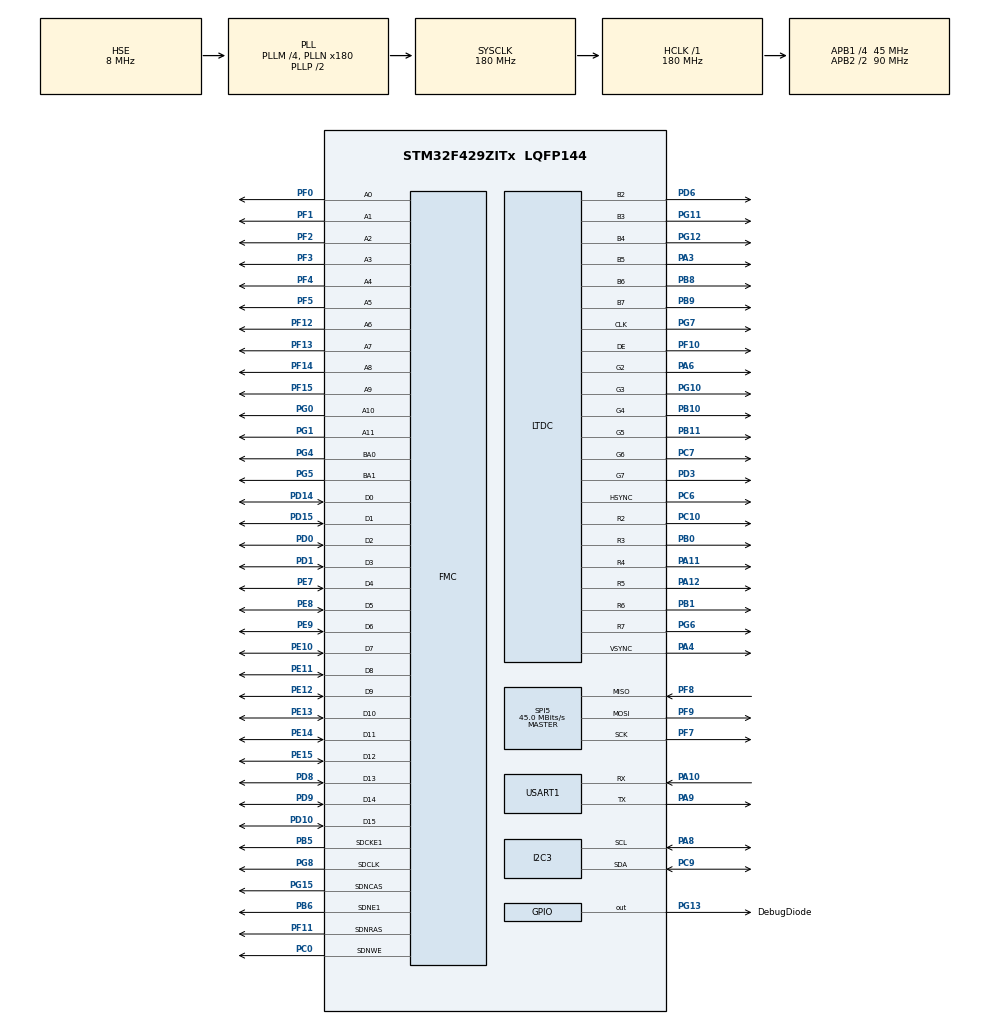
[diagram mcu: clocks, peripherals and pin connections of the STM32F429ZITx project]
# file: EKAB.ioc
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DMA2D.Mode=DMA2D_R2M
FMC.CASLatency1=FMC_SDRAM_CAS_LATENCY_3
FMC.ExitSelfRefreshDelay1=7
FMC.LoadToActiveDelay1=2
FMC.RCDDelay1=2
FMC.RPDelay1=2
FMC.RPDelay2=2
FMC.RowCycleDelay1=7
FMC.RowCycleDelay2=7
FMC.SDClockPeriod1=FMC_SDRAM_CLOCK_PERIOD_3
FMC.SDClockPeriod2=FMC_SDRAM_CLOCK_PERIOD_3
FMC.SelfRefreshTime1=4
FMC.WriteRecoveryTime1=3
FREERTOS.Tasks01=mainTask,24,128,mainTaskfunction,Default,NULL,Dynamic,NULL,NULL;painterTask,24,128,painterTaskFunction,Default,NULL,Dynamic,NULL,NULL
LTDC.ActiveH=320
LTDC.ActiveW=240
Mcu.Family=STM32F4
Mcu.Name=STM32F429ZITx
Mcu.Package=LQFP144
NVIC.PriorityGroup=NVIC_PRIORITYGROUP_4
NVIC.TIM6_DAC_IRQn=true\:0\:0\:false\:false\:true\:false\:false\:true
NVIC.TimeBase=TIM6_DAC_IRQn
NVIC.TimeBaseIP=TIM6
PA10.Mode=Asynchronous
PA10.Signal=USART1_RX
PA11.Mode=RGB666
PA11.Signal=LTDC_R4
PA12.Mode=RGB666
PA12.Signal=LTDC_R5
PA13.Mode=Serial_Wire
PA13.Signal=SYS_JTMS-SWDIO
PA14.Mode=Serial_Wire
PA14.Signal=SYS_JTCK-SWCLK
PA3.Mode=RGB666
PA3.Signal=LTDC_B5
PA4.Mode=RGB666
PA4.Signal=LTDC_VSYNC
PA6.Mode=RGB666
PA6.Signal=LTDC_G2
PA8.Mode=I2C
PA8.Signal=I2C3_SCL
PA9.Mode=Asynchronous
PA9.Signal=USART1_TX
PB0.Mode=RGB666
PB0.Signal=LTDC_R3
PB1.Mode=RGB666
PB1.Signal=LTDC_R6
PB10.Mode=RGB666
PB10.Signal=LTDC_G4
PB11.Mode=RGB666
PB11.Signal=LTDC_G5
PB5.Mode=SdramChipSelect2_1
PB5.Signal=FMC_SDCKE1
PB6.Mode=SdramChipSelect2_1
PB6.Signal=FMC_SDNE1
PB8.Mode=RGB666
PB8.Signal=LTDC_B6
PB9.Mode=RGB666
PB9.Signal=LTDC_B7
PC0.Signal=FMC_SDNWE
PC10.Mode=RGB666
PC10.Signal=LTDC_R2
PC6.Mode=RGB666
PC6.Signal=LTDC_HSYNC
PC7.Mode=RGB666
PC7.Signal=LTDC_G6
PC9.Mode=I2C
PC9.Signal=I2C3_SDA
PD0.Signal=FMC_D2_DA2
PD1.Signal=FMC_D3_DA3
PD10.Signal=FMC_D15_DA15
PD14.Signal=FMC_D0_DA0
PD15.Signal=FMC_D1_DA1
PD3.Mode=RGB666
PD3.Signal=LTDC_G7
PD6.Mode=RGB666
PD6.Signal=LTDC_B2
PD8.Signal=FMC_D13_DA13
PD9.Signal=FMC_D14_DA14
PE10.Signal=FMC_D7_DA7
PE11.Signal=FMC_D8_DA8
PE12.Signal=FMC_D9_DA9
PE13.Signal=FMC_D10_DA10
PE14.Signal=FMC_D11_DA11
PE15.Signal=FMC_D12_DA12
PE7.Signal=FMC_D4_DA4
PE8.Signal=FMC_D5_DA5
PE9.Signal=FMC_D6_DA6
PF0.Signal=FMC_A0
PF1.Signal=FMC_A1
PF10.Mode=RGB666
PF10.Signal=LTDC_DE
PF11.Signal=FMC_SDNRAS
PF12.Signal=FMC_A6
PF13.Signal=FMC_A7
PF14.Signal=FMC_A8
PF15.Signal=FMC_A9
PF2.Signal=FMC_A2
PF3.Signal=FMC_A3
PF4.Signal=FMC_A4
PF5.Signal=FMC_A5
PF7.Mode=Full_Duplex_Master
PF7.Signal=SPI5_SCK
PF8.Mode=Full_Duplex_Master
PF8.Signal=SPI5_MISO
PF9.Mode=Full_Duplex_Master
PF9.Signal=SPI5_MOSI
PG0.Signal=FMC_A10
PG1.Signal=FMC_A11
PG10.Mode=RGB666
PG10.Signal=LTDC_G3
PG11.Mode=RGB666
PG11.Signal=LTDC_B3
PG12.Mode=RGB666
PG12.Signal=LTDC_B4
PG13.GPIO_Label=DebugDiode
PG13.GPIO_ModeDefaultOutputPP=GPIO_MODE_OUTPUT_PP
PG13.Signal=GPIO_Output
PG15.Signal=FMC_SDNCAS
PG4.Signal=FMC_A14_BA0
PG5.Signal=FMC_A15_BA1
PG6.Mode=RGB666
PG6.Signal=LTDC_R7
PG7.Mode=RGB666
PG7.Signal=LTDC_CLK
PG8.Signal=FMC_SDCLK
PH0/OSC_IN.Mode=HSE-External-Oscillator
PH0/OSC_IN.Signal=RCC_OSC_IN
PH1/OSC_OUT.Mode=HSE-External-Oscillator
PH1/OSC_OUT.Signal=RCC_OSC_OUT
ProjectManager.HeapSize=0x200
ProjectManager.StackSize=0x400
ProjectManager.TargetToolchain=STM32CubeIDE
RCC.48MHZClocksFreq_Value=90000000
RCC.AHBFreq_Value=180000000
RCC.APB1CLKDivider=RCC_HCLK_DIV4
RCC.APB1Freq_Value=45000000
RCC.APB1TimFreq_Value=90000000
RCC.APB2CLKDivider=RCC_HCLK_DIV2
RCC.APB2Freq_Value=90000000
RCC.APB2TimFreq_Value=180000000
RCC.CortexFreq_Value=180000000
RCC.HCLKFreq_Value=180000000
RCC.HSE_VALUE=8000000
RCC.HSI_VALUE=16000000
RCC.LSE_VALUE=32768
RCC.PLLM=4
RCC.PLLN=180
RCC.PLLSAIDivR=RCC_PLLSAIDIVR_8
RCC.PLLSAIN=192
RCC.PLLSAIR=4
RCC.PLLSourceVirtual=RCC_PLLSOURCE_HSE
RCC.PWR_Regulator_Voltage_Scale=PWR_REGULATOR_VOLTAGE_SCALE1
RCC.SYSCLKFreq_VALUE=180000000
RCC.SYSCLKSource=RCC_SYSCLKSOURCE_PLLCLK
RCC.VCOOutputFreq_Value=360000000
SH.FMC_A0.0=FMC_A0,12b-sda1
SH.FMC_A1.0=FMC_A1,12b-sda1
SH.FMC_A10.0=FMC_A10,12b-sda1
SH.FMC_A11.0=FMC_A11,12b-sda1
SH.FMC_A14_BA0.0=FMC_BA0,FourSdramBanks1
SH.FMC_A15_BA1.0=FMC_BA1,FourSdramBanks1
SH.FMC_A2.0=FMC_A2,12b-sda1
SH.FMC_A3.0=FMC_A3,12b-sda1
SH.FMC_A4.0=FMC_A4,12b-sda1
SH.FMC_A5.0=FMC_A5,12b-sda1
SH.FMC_A6.0=FMC_A6,12b-sda1
SH.FMC_A7.0=FMC_A7,12b-sda1
SH.FMC_A8.0=FMC_A8,12b-sda1
SH.FMC_A9.0=FMC_A9,12b-sda1
SH.FMC_D0_DA0.0=FMC_D0,sd-16b-d1
SH.FMC_D10_DA10.0=FMC_D10,sd-16b-d1
SH.FMC_D11_DA11.0=FMC_D11,sd-16b-d1
SH.FMC_D12_DA12.0=FMC_D12,sd-16b-d1
SH.FMC_D13_DA13.0=FMC_D13,sd-16b-d1
SH.FMC_D14_DA14.0=FMC_D14,sd-16b-d1
SH.FMC_D15_DA15.0=FMC_D15,sd-16b-d1
SH.FMC_D1_DA1.0=FMC_D1,sd-16b-d1
SH.FMC_D2_DA2.0=FMC_D2,sd-16b-d1
SH.FMC_D3_DA3.0=FMC_D3,sd-16b-d1
SH.FMC_D4_DA4.0=FMC_D4,sd-16b-d1
SH.FMC_D5_DA5.0=FMC_D5,sd-16b-d1
SH.FMC_D6_DA6.0=FMC_D6,sd-16b-d1
SH.FMC_D7_DA7.0=FMC_D7,sd-16b-d1
SH.FMC_D8_DA8.0=FMC_D8,sd-16b-d1
SH.FMC_D9_DA9.0=FMC_D9,sd-16b-d1
SH.FMC_SDCLK.0=FMC_SDCLK,12b-sda1
SH.FMC_SDNCAS.0=FMC_SDNCAS,12b-sda1
SH.FMC_SDNRAS.0=FMC_SDNRAS,12b-sda1
SH.FMC_SDNWE.0=FMC_SDNWE,12b-sda1
SPI5.BaudRatePrescaler=SPI_BAUDRATEPRESCALER_2
SPI5.CalculateBaudRate=45.0 MBits/s
SPI5.Direction=SPI_DIRECTION_2LINES
SPI5.Mode=SPI_MODE_MASTER
SPI5.VirtualType=VM_MASTER
USART1.VirtualMode=VM_ASYNC
VP_DMA2D_VS_DMA2D.Mode=DMA2D_Activate
VP_FREERTOS_VS_CMSIS_V2.Mode=CMSIS_V2
VP_SYS_VS_tim6.Mode=TIM6
board=custom

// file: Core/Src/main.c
/* USER CODE BEGIN Header */
/**
 ******************************************************************************
 * @file           : main.c
 * @brief          : Main program body
 ******************************************************************************
 * @attention
 *
 * <h2><center>&copy; Copyright (c) 2020 STMicroelectronics.
 * All rights reserved.</center></h2>
 *
 * This software component is licensed by ST under BSD 3-Clause license,
 * the "License"; You may not use this file except in compliance with the
 * License. You may obtain a copy of the License at:
 *                        opensource.org/licenses/BSD-3-Clause
 *
 ******************************************************************************
 */
/* USER CODE END Header */

#include "main.h"
#include "cmsis_os.h"
#include "dma2d.h"
#include "i2c.h"
#include "ltdc.h"
#include "spi.h"
#include "usart.h"
#include "gpio.h"
#include "fmc.h"

/* USER CODE BEGIN Includes */
#include "chooseViewStructure.h"
#include "paintIntro.h"
#include "paintInterface.h"
#include "chooseCanvaInterface.h"

//#include "../../Drivers/BSP/STM32F429I-Discovery/stm32f429i_discovery_lcd.h"
/* USER CODE END Includes */

void SystemClock_Config(void);
void MX_FREERTOS_Init(void);

int main(void)
{

  /* MCU Configuration--------------------------------------------------------*/

  /* Reset of all peripherals, Initializes the Flash interface and the Systick. */
  HAL_Init();

  /* Configure the system clock */
  SystemClock_Config();

  /* Initialize all configured peripherals */
  MX_GPIO_Init();
  MX_DMA2D_Init();
  MX_FMC_Init();
  MX_I2C3_Init();
  MX_LTDC_Init();
  MX_SPI5_Init();
  MX_USART1_UART_Init();
  /* USER CODE BEGIN 2 */
	initLCD();
	printHelloScreen();
	configTS();
	showChooseCanvaInterface();
	//showPaintInterface();
  /* USER CODE END 2 */

  /* Init scheduler */
  osKernelInitialize();  /* Call init function for freertos objects (in freertos.c) */
  MX_FREERTOS_Init();
  /* Start scheduler */
  osKernelStart();

  /* We should never get here as control is now taken by the scheduler */
  /* Infinite loop */
	while (1)
	{

	}
}

void SystemClock_Config(void)
{
  RCC_OscInitTypeDef RCC_OscInitStruct = {0};
  RCC_ClkInitTypeDef RCC_ClkInitStruct = {0};
  RCC_PeriphCLKInitTypeDef PeriphClkInitStruct = {0};

  /** Configure the main internal regulator output voltage
  */
  __HAL_RCC_PWR_CLK_ENABLE();
  __HAL_PWR_VOLTAGESCALING_CONFIG(PWR_REGULATOR_VOLTAGE_SCALE1);
  /** Initializes the CPU, AHB and APB busses clocks
  */
  RCC_OscInitStruct.OscillatorType = RCC_OSCILLATORTYPE_HSE;
  RCC_OscInitStruct.HSEState = RCC_HSE_ON;
  RCC_OscInitStruct.PLL.PLLState = RCC_PLL_ON;
  RCC_OscInitStruct.PLL.PLLSource = RCC_PLLSOURCE_HSE;
  RCC_OscInitStruct.PLL.PLLM = 4;
  RCC_OscInitStruct.PLL.PLLN = 180;
  RCC_OscInitStruct.PLL.PLLP = RCC_PLLP_DIV2;
  RCC_OscInitStruct.PLL.PLLQ = 4;
  if (HAL_RCC_OscConfig(&RCC_OscInitStruct) != HAL_OK)
  {
    Error_Handler();
  }
  /** Activate the Over-Drive mode
  */
  if (HAL_PWREx_EnableOverDrive() != HAL_OK)
  {
    Error_Handler();
  }
  /** Initializes the CPU, AHB and APB busses clocks
  */
  RCC_ClkInitStruct.ClockType = RCC_CLOCKTYPE_HCLK|RCC_CLOCKTYPE_SYSCLK
                              |RCC_CLOCKTYPE_PCLK1|RCC_CLOCKTYPE_PCLK2;
  RCC_ClkInitStruct.SYSCLKSource = RCC_SYSCLKSOURCE_PLLCLK;
  RCC_ClkInitStruct.AHBCLKDivider = RCC_SYSCLK_DIV1;
  RCC_ClkInitStruct.APB1CLKDivider = RCC_HCLK_DIV4;
  RCC_ClkInitStruct.APB2CLKDivider = RCC_HCLK_DIV2;

  if (HAL_RCC_ClockConfig(&RCC_ClkInitStruct, FLASH_LATENCY_5) != HAL_OK)
  {
    Error_Handler();
  }
  PeriphClkInitStruct.PeriphClockSelection = RCC_PERIPHCLK_LTDC;
  PeriphClkInitStruct.PLLSAI.PLLSAIN = 192;
  PeriphClkInitStruct.PLLSAI.PLLSAIR = 4;
  PeriphClkInitStruct.PLLSAIDivR = RCC_PLLSAIDIVR_8;
  if (HAL_RCCEx_PeriphCLKConfig(&PeriphClkInitStruct) != HAL_OK)
  {
    Error_Handler();
  }
}

 /**
  * @brief  Period elapsed callback in non blocking mode
  * @note   This function is called  when TIM6 interrupt took place, inside
  * HAL_TIM_IRQHandler(). It makes a direct call to HAL_IncTick() to increment
  * a global variable "uwTick" used as application time base.
  * @param  htim : TIM handle
  * @retval None
  */
void HAL_TIM_PeriodElapsedCallback(TIM_HandleTypeDef *htim)
{
  if (htim->Instance == TIM6) {
    HAL_IncTick();
  }
}

void Error_Handler(void)
{
}

/************************ (C) COPYRIGHT STMicroelectronics *****END OF FILE****/

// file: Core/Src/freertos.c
/* USER CODE BEGIN Header */
/**
  ******************************************************************************
  * File Name          : freertos.c
  * Description        : Code for freertos applications
  ******************************************************************************
  * @attention
  *
  * <h2><center>&copy; Copyright (c) 2020 STMicroelectronics.
  * All rights reserved.</center></h2>
  *
  * This software component is licensed by ST under Ultimate Liberty license
  * SLA0044, the "License"; You may not use this file except in compliance with
  * the License. You may obtain a copy of the License at:
  *                             www.st.com/SLA0044
  *
  ******************************************************************************
  */
/* USER CODE END Header */

#include "FreeRTOS.h"
#include "task.h"
#include "main.h"
#include "cmsis_os.h"

/* USER CODE BEGIN Includes */
#include "chooseViewStructure.h"
#include "paintInterface.h"
#include "chooseCanvaInterface.h"
/* USER CODE END Includes */

/* USER CODE BEGIN PD */
uint8_t canvas = '0';
int printer = 0;
/* USER CODE END PD */

/* Definitions for mainTask */
osThreadId_t mainTaskHandle;
const osThreadAttr_t mainTask_attributes = {
  .name = "mainTask",
  .priority = (osPriority_t) osPriorityNormal,
  .stack_size = 128 * 4
};
/* Definitions for painterTask */
osThreadId_t painterTaskHandle;
const osThreadAttr_t painterTask_attributes = {
  .name = "painterTask",
  .priority = (osPriority_t) osPriorityNormal,
  .stack_size = 128 * 4
};

void mainTaskfunction(void *argument);
void painterTaskFunction(void *argument);

void MX_FREERTOS_Init(void); /* (MISRA C 2004 rule 8.1) */

void MX_FREERTOS_Init(void) {

  /* Create the thread(s) */
  /* creation of mainTask */
  mainTaskHandle = osThreadNew(mainTaskfunction, NULL, &mainTask_attributes);

  /* creation of painterTask */
  painterTaskHandle = osThreadNew(painterTaskFunction, NULL, &painterTask_attributes);

}

void mainTaskfunction(void *argument)
{
  /* USER CODE BEGIN mainTaskfunction */
  /* Infinite loop */
  for(;;)
  {
	  if(printer == 0)
	  {
		  switch(activeView)
		  		  	  		{
		  		  	  		case Canvas1:
		  		  	  			canvas = '1';
		  		  	  			clearWorkspace(canvas);

		  		  	  			loadPartOfSketch(10, 0x080C0000, 38, 38);
		  		  	  			loadPartOfSketch(11, 0x080E0000, 38, 179);

		  		  	  			osDelay(500);
		  		  	  			printer = 1;
		  		  	  			break;
		  		  	  		case Canvas2:
		  		  	  			canvas = '2';
		  		  	  			clearWorkspace(canvas);

		  		  	  			loadPartOfSketch(8, 0x08080000, 38, 38);
		  		  	  			loadPartOfSketch(9, 0x080A0000, 38, 179);

		  		  	  			osDelay(500);
		  		  	  			printer = 1;
		  		  	  			break;
		  		  	  		case ChooseScreen:
		  		  	  			showChooseCanvaInterface();
		  		  	  			choose();
		  		  	  			break;
		  		  	  		case Info:
		  		  	  			serviceInfoScreen();
		  		  	  			break;
		  		  	  		default:

		  		  	  			break;

		  		  	  		}
	  }

  }
    osDelay(1);
  }

  /* USER CODE END mainTaskfunction */

void painterTaskFunction(void *argument)
{
  /* USER CODE BEGIN painterTaskFunction */
  /* Infinite loop */
  for(;;)
  {
	  if(printer == 1) paintProcess(canvas);
	  if(activeView == ChooseScreen) printer = 0;
	  osDelay(1);
  }
  /* USER CODE END painterTaskFunction */
}

/************************ (C) COPYRIGHT STMicroelectronics *****END OF FILE****/
